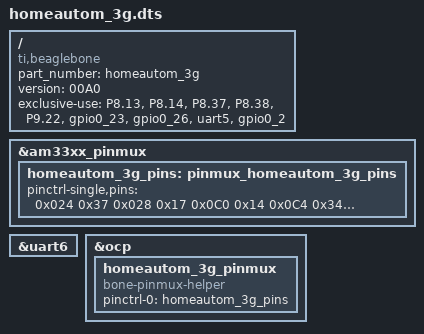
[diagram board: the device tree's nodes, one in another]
/*
 * This is a template-generated file from BoneScript
 * http://kilobaser.com/blog/2014-07-28-beaglebone-black-devicetreeoverlay-generator
 */

/dts-v1/;
/plugin/;

/{
	/* identification */
	compatible = "ti,beaglebone", "ti,beaglebone-black";
	part_number = "homeautom_3g";
	version = "00A0";

	/* state the resources this cape uses */
	exclusive-use =
		/* the pin header uses */
		"P8.13",
		"P8.14",
		"P8.37",
		"P8.38",
		"P9.22",
		/* the hardware ip uses */
		"gpio0_23",
		"gpio0_26",
		"uart5",
		"gpio0_2";

	fragment@0 {
		target = <&am33xx_pinmux>;
		__overlay__ {
			homeautom_3g_pins: pinmux_homeautom_3g_pins {
				pinctrl-single,pins = <
					0x024 0x37
					0x028 0x17
					0x0C0 0x14
					0x0C4 0x34
					0x150 0x7
				>;
			};
		};
	};

	fragment@1 {
		target = <&uart6>;
		__overlay__ {
			status = "okay";
		};
	};

	fragment@2 {
		target = <&ocp>;
		__overlay__ {
			homeautom_3g_pinmux {
				compatible = "bone-pinmux-helper";
				pinctrl-names = "default";
				pinctrl-0 = <&homeautom_3g_pins>;
				status = "okay";
			};
		};
	};
};

